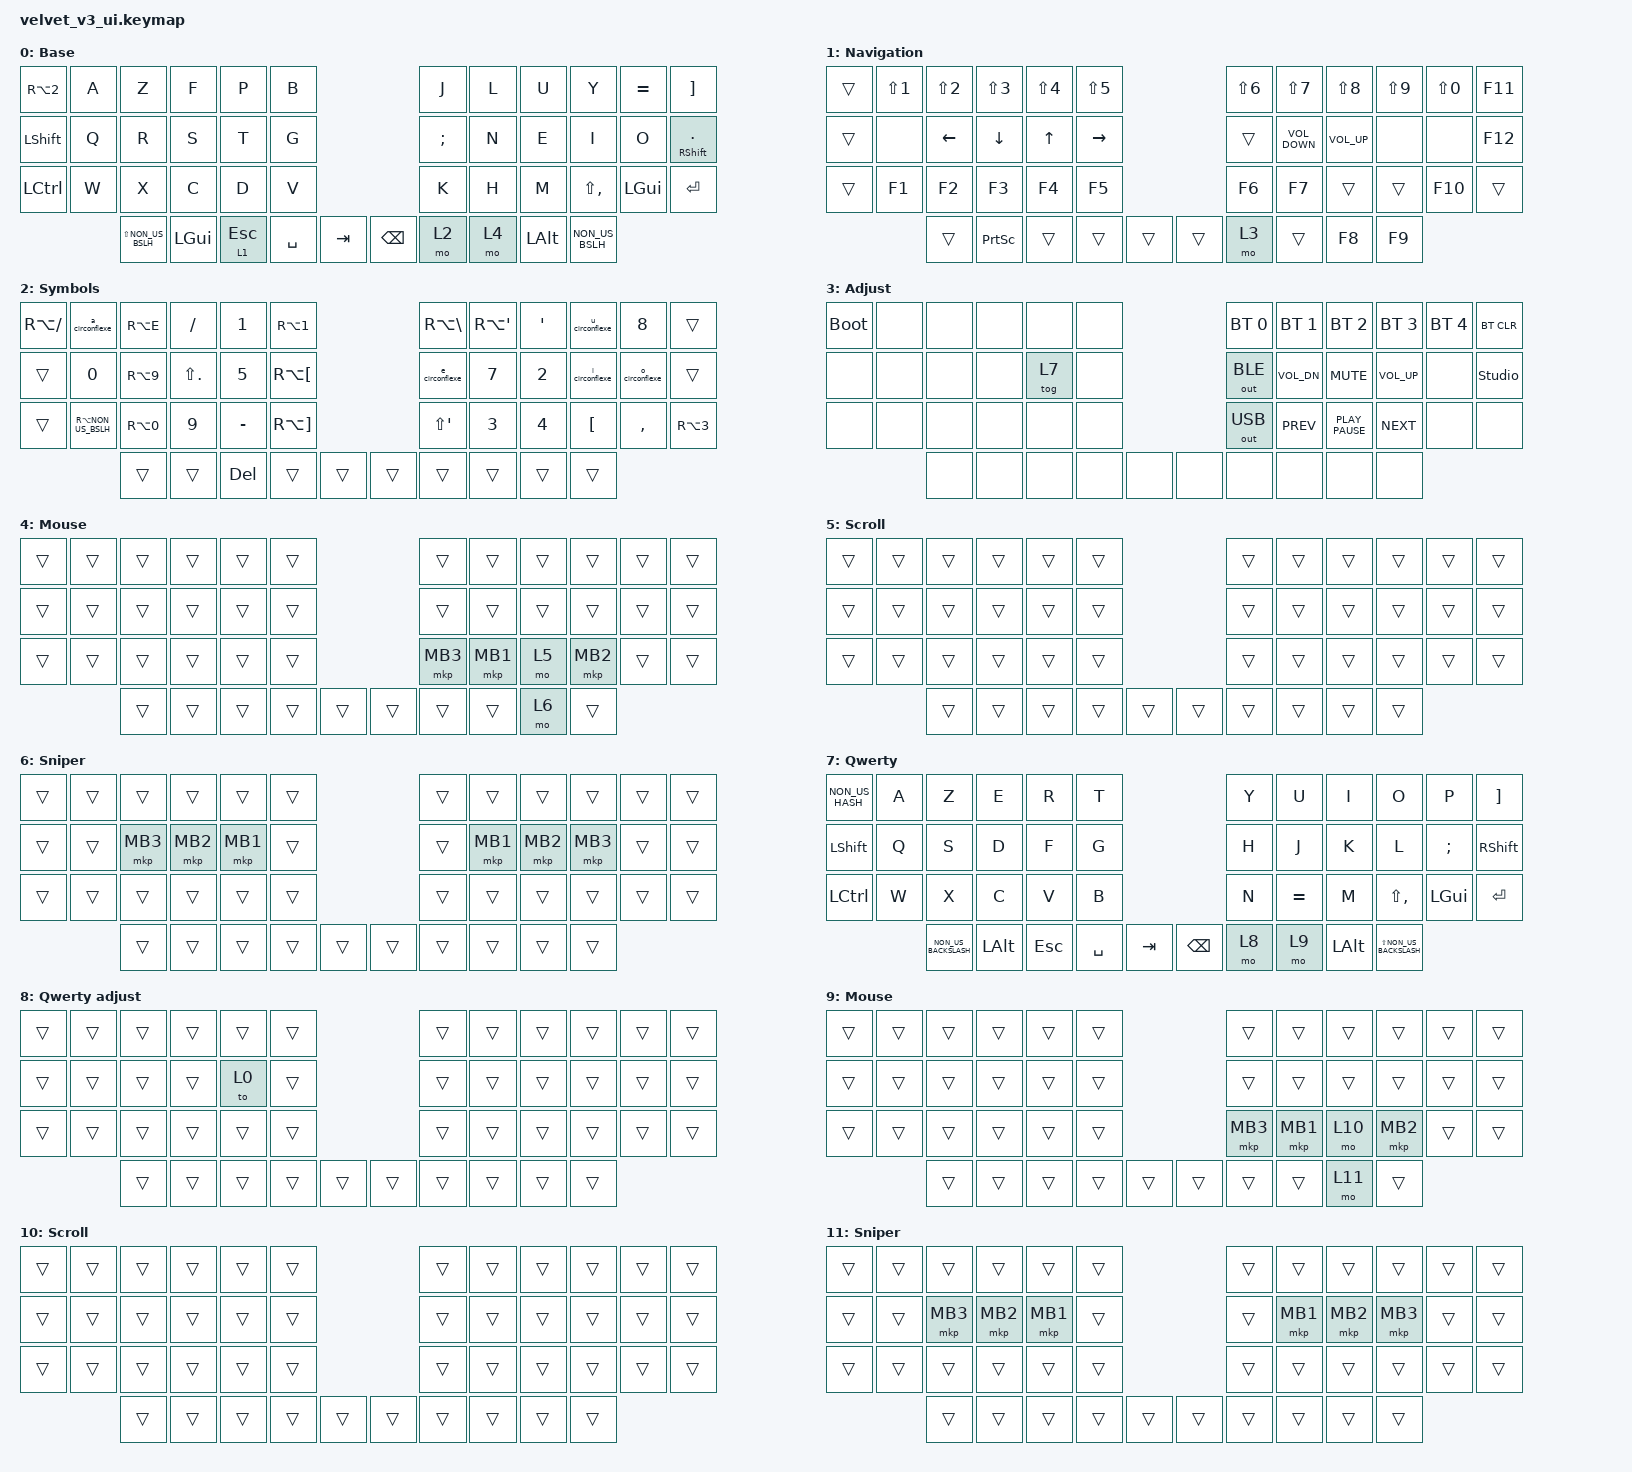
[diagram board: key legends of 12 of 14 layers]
#include "keys_ru.h"
#include <dt-bindings/zmk/input_transform.h>
#include <input/processors.dtsi>
#include <zephyr/dt-bindings/input/input-event-codes.h>
#include <behaviors.dtsi>
#include <dt-bindings/zmk/bt.h>
#include <dt-bindings/zmk/keys.h>
#include <dt-bindings/zmk/outputs.h>
#include <dt-bindings/zmk/pointing.h>

/ {
    behaviors {
        cap_sen: cap_sen {
            compatible = "zmk,behavior-hold-tap";
            label = "CAP_SEN";
            bindings = <&mo>, <&mkp>;

            #binding-cells = <2>;
            tapping-term-ms = <150>;
            hold-while-undecided;
        };
    };

    macros {
        a_circonflexe: a_circonflexe {
            compatible = "zmk,behavior-macro";
            #binding-cells = <0>;
            bindings = <&kp LEFT_BRACKET &kp Q>;
            label = "A_CIRCONFLEXE";
        };

        e_circonflexe: e_circonflexe {
            compatible = "zmk,behavior-macro";
            #binding-cells = <0>;
            bindings = <&kp LEFT_BRACKET &kp E>;
            label = "E_CIRCONFLEXE";
        };

        o_circonflexe: o_circonflexe {
            compatible = "zmk,behavior-macro";
            #binding-cells = <0>;
            bindings = <&kp LEFT_BRACKET &kp O>;
            label = "O_CIRCONFLEXE";
        };

        i_circonflexe: i_circonflexe {
            compatible = "zmk,behavior-macro";
            #binding-cells = <0>;
            bindings = <&kp LEFT_BRACKET &kp I>;
            label = "I_CIRCONFLEXE";
        };

        u_circonflexe: u_circonflexe {
            compatible = "zmk,behavior-macro";
            #binding-cells = <0>;
            bindings = <&kp LEFT_BRACKET &kp U>;
            label = "U_CIRCONFLEXE";
        };
    };

    keymap {
        compatible = "zmk,keymap";

        base {
            bindings = <
&kp RA(NUMBER_2)  &kp A  &kp Z                &kp F     &kp P      &kp B                                &kp J     &kp L  &kp U         &kp Y            &kp EQUAL  &kp RIGHT_BRACKET
&kp LEFT_SHIFT    &kp Q  &kp R                &kp S     &kp T      &kp G                                &kp SEMI  &kp N  &kp E         &kp I            &kp O      &mt RIGHT_SHIFT PERIOD
&kp LCTRL         &kp W  &kp X                &kp C     &kp D      &kp V                                &kp K     &kp H  &kp M         &kp LS(COMMA)    &kp LGUI   &kp RETURN
                         &kp LS(NON_US_BSLH)  &kp LGUI  &lt 1 ESC  &kp SPACE  &kp TAB    &kp BACKSPACE  &mo 2     &mo 4  &kp LEFT_ALT  &kp NON_US_BSLH
            >;

            display-name = "Base";
        };

        nav {
            bindings = <
&trans  &kp LS(N1)  &kp LS(N2)      &kp LS(N3)       &kp LS(N4)  &kp LS(N5)                         &kp LS(N6)  &kp LS(N7)         &kp LS(N8)       &kp LS(N9)  &kp LS(N0)  &kp F11
&trans  &none       &kp LEFT_ARROW  &kp DOWN         &kp UP      &kp RIGHT_ARROW                    &trans      &kp C_VOLUME_DOWN  &kp C_VOLUME_UP  &none       &none       &kp F12
&trans  &kp F1      &kp F2          &kp F3           &kp F4      &kp F5                             &kp F6      &kp F7             &trans           &trans      &kp F10     &trans
                    &trans          &kp PRINTSCREEN  &trans      &trans           &trans    &trans  &mo 3       &trans             &kp F8           &kp F9
            >;

            display-name = "Navigation";
        };

        sym {
            bindings = <
&kp RA(SLASH)  &a_circonflexe       &kp RA(E)   &kp FSLH        &kp N1      &kp RA(N1)                               &kp RA(BACKSLASH)     &kp RA(SINGLE_QUOTE)  &kp SINGLE_QUOTE  &u_circonflexe    &kp N8          &trans
&trans         &kp N0               &kp RA(N9)  &kp LS(PERIOD)  &kp N5      &kp RA(LEFT_BRACKET)                     &e_circonflexe        &kp N7                &kp N2            &i_circonflexe    &o_circonflexe  &trans
&trans         &kp RA(NON_US_BSLH)  &kp RA(N0)  &kp N9          &kp MINUS   &kp RA(RIGHT_BRACKET)                    &kp LS(SINGLE_QUOTE)  &kp N3                &kp N4            &kp LEFT_BRACKET  &kp COMMA       &kp RA(N3)
                                    &trans      &trans          &kp DELETE  &trans                 &trans    &trans  &trans                &trans                &trans            &trans
            >;

            display-name = "Symbols";
        };

        adj {
            bindings = <
&bootloader  &none  &none  &none  &none   &none                  &bt BT_SEL 0  &bt BT_SEL 1  &bt BT_SEL 2      &bt BT_SEL 3  &bt BT_SEL 4  &bt BT_CLR
&none        &none  &none  &none  &tog 7  &none                  &out OUT_BLE  &kp C_VOL_DN  &kp K_MUTE        &kp C_VOL_UP  &none         &studio_unlock
&none        &none  &none  &none  &none   &none                  &out OUT_USB  &kp K_PREV    &kp K_PLAY_PAUSE  &kp K_NEXT    &none         &none
                    &none  &none  &none   &none  &none    &none  &none         &none         &none             &none
            >;

            display-name = "Adjust";
        };

        mouse {
            bindings = <
&trans  &trans  &trans  &trans  &trans  &trans                    &trans    &trans    &trans  &trans    &trans  &trans
&trans  &trans  &trans  &trans  &trans  &trans                    &trans    &trans    &trans  &trans    &trans  &trans
&trans  &trans  &trans  &trans  &trans  &trans                    &mkp MB3  &mkp MB1  &mo 5   &mkp MB2  &trans  &trans
                &trans  &trans  &trans  &trans  &trans    &trans  &trans    &trans    &mo 6   &trans
            >;

            display-name = "Mouse";
        };

        scroll {
            bindings = <
&trans  &trans  &trans  &trans  &trans  &trans                    &trans  &trans  &trans  &trans  &trans  &trans
&trans  &trans  &trans  &trans  &trans  &trans                    &trans  &trans  &trans  &trans  &trans  &trans
&trans  &trans  &trans  &trans  &trans  &trans                    &trans  &trans  &trans  &trans  &trans  &trans
                &trans  &trans  &trans  &trans  &trans    &trans  &trans  &trans  &trans  &trans
            >;

            display-name = "Scroll";
        };

        sniper {
            bindings = <
&trans  &trans  &trans    &trans    &trans    &trans                    &trans  &trans    &trans    &trans    &trans  &trans
&trans  &trans  &mkp MB3  &mkp MB2  &mkp MB1  &trans                    &trans  &mkp MB1  &mkp MB2  &mkp MB3  &trans  &trans
&trans  &trans  &trans    &trans    &trans    &trans                    &trans  &trans    &trans    &trans    &trans  &trans
                &trans    &trans    &trans    &trans  &trans    &trans  &trans  &trans    &trans    &trans
            >;

            display-name = "Sniper";
        };

        qwerty {
            bindings = <
&kp NON_US_HASH   &kp A  &kp Z                 &kp E         &kp R    &kp T                                &kp Y  &kp U      &kp I         &kp O                     &kp P          &kp RIGHT_BRACKET
&kp LEFT_SHIFT    &kp Q  &kp S                 &kp D         &kp F    &kp G                                &kp H  &kp J      &kp K         &kp L                     &kp SEMICOLON  &kp RIGHT_SHIFT
&kp LEFT_CONTROL  &kp W  &kp X                 &kp C         &kp V    &kp B                                &kp N  &kp EQUAL  &kp M         &kp LS(COMMA)             &kp LEFT_GUI   &kp ENTER
                         &kp NON_US_BACKSLASH  &kp LEFT_ALT  &kp ESC  &kp SPACE  &kp TAB    &kp BACKSPACE  &mo 8  &mo 9      &kp LEFT_ALT  &kp LS(NON_US_BACKSLASH)
            >;

            display-name = "Qwerty";
        };

        qwerty-adj {
            bindings = <
&trans  &trans  &trans  &trans  &trans  &trans                    &trans  &trans  &trans  &trans  &trans  &trans
&trans  &trans  &trans  &trans  &to 0   &trans                    &trans  &trans  &trans  &trans  &trans  &trans
&trans  &trans  &trans  &trans  &trans  &trans                    &trans  &trans  &trans  &trans  &trans  &trans
                &trans  &trans  &trans  &trans  &trans    &trans  &trans  &trans  &trans  &trans
            >;

            display-name = "Qwerty adjust";
        };

        qwerty-mouse {
            display-name = "Mouse";
            bindings = <
&trans  &trans  &trans  &trans  &trans  &trans                    &trans    &trans    &trans  &trans    &trans  &trans
&trans  &trans  &trans  &trans  &trans  &trans                    &trans    &trans    &trans  &trans    &trans  &trans
&trans  &trans  &trans  &trans  &trans  &trans                    &mkp MB3  &mkp MB1  &mo 10  &mkp MB2  &trans  &trans
                &trans  &trans  &trans  &trans  &trans    &trans  &trans    &trans    &mo 11  &trans
            >;
        };

        qwerty-scroll {
            display-name = "Scroll";
            bindings = <
&trans  &trans  &trans  &trans  &trans  &trans                    &trans  &trans  &trans  &trans  &trans  &trans
&trans  &trans  &trans  &trans  &trans  &trans                    &trans  &trans  &trans  &trans  &trans  &trans
&trans  &trans  &trans  &trans  &trans  &trans                    &trans  &trans  &trans  &trans  &trans  &trans
                &trans  &trans  &trans  &trans  &trans    &trans  &trans  &trans  &trans  &trans
            >;
        };

        qwerty-sniper {
            display-name = "Sniper";
            bindings = <
&trans  &trans  &trans    &trans    &trans    &trans                    &trans  &trans    &trans    &trans    &trans  &trans
&trans  &trans  &mkp MB3  &mkp MB2  &mkp MB1  &trans                    &trans  &mkp MB1  &mkp MB2  &mkp MB3  &trans  &trans
&trans  &trans  &trans    &trans    &trans    &trans                    &trans  &trans    &trans    &trans    &trans  &trans
                &trans    &trans    &trans    &trans  &trans    &trans  &trans  &trans    &trans    &trans
            >;
        };

        User2 {
            bindings = <
&trans  &trans  &trans  &trans  &trans  &trans                    &trans  &trans  &trans  &trans  &trans  &trans
&trans  &trans  &trans  &trans  &trans  &trans                    &trans  &trans  &trans  &trans  &trans  &trans
&trans  &trans  &trans  &trans  &trans  &trans                    &trans  &trans  &trans  &trans  &trans  &trans
                &trans  &trans  &trans  &trans  &trans    &trans  &trans  &trans  &trans  &trans
            >;

            display-name = "User2";
        };

        User3 {
            bindings = <
&trans  &trans  &trans  &trans  &trans  &trans                    &trans  &trans  &trans  &trans  &trans  &trans
&trans  &trans  &trans  &trans  &trans  &trans                    &trans  &trans  &trans  &trans  &trans  &trans
&trans  &trans  &trans  &trans  &trans  &trans                    &trans  &trans  &trans  &trans  &trans  &trans
                &trans  &trans  &trans  &trans  &trans    &trans  &trans  &trans  &trans  &trans
            >;

            display-name = "User3";
        };
    };
};

&trackball { cpi = <800>; };

&trackball_listener {
    input-processors = <&zip_xy_scaler 9 20>;

    scroller {
        layers = <5>;
        input-processors =
            <&zip_xy_transform INPUT_TRANSFORM_Y_INVERT>,
            <&zip_xy_scaler 1 48>,
            <&zip_xy_to_scroll_mapper>;
    };

    sniper {
        layers = <6>;
        input-processors = <&zip_xy_scaler 1 5>;
    };
};
